VERSION ""

NS_ :

BS_:

BU_:
VAL_TABLE_ OdoDTCFrameSelr 1 "The last security event request" 0 "The first security event request" ;
VAL_TABLE_ OdometerRoutineRequestToHMI 7 "NA" 6 "Reserved" 5 "Reserved" 4 "ResetBackupODM_Storage " 3 "ClearNotActiveODM_DTC " 2 "ReadOdometerDTC" 1 "WriteDCUOdometerValueToHMI" 0 "RetrieveOdometerBackupValue" ;
VAL_TABLE_ ODM_StatusFlags 3 "Reserved" 2 "NA" 1 "Fault" 0 "NoFault" ;

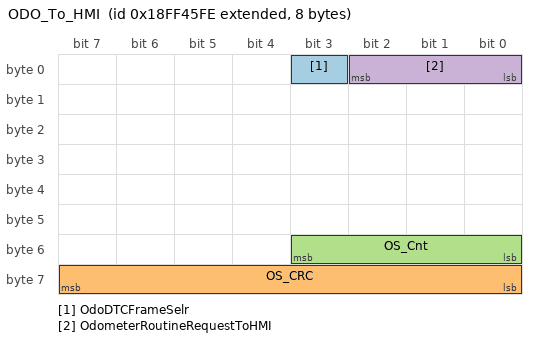
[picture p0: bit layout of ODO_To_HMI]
BO_ 2566866430 ODO_To_HMI: 8 Vector__XXX
 SG_ OdoDTCFrameSelr : 3|1@1+ (1,0) [0|0] "" Vector__XXX
 SG_ OS_CRC : 56|8@1+ (1,0) [0|255] "" Vector__XXX
 SG_ OS_Cnt : 48|4@1+ (1,0) [0|15] "" Vector__XXX
 SG_ OdometerRoutineRequestToHMI : 0|3@1+ (1,0) [0|7] "" Vector__XXX

CM_ SG_ 2566866430 OdoDTCFrameSelr "Odometer DTC Frame selector for request to HMI";
CM_ SG_ 2566866430 OdometerRoutineRequestToHMI "Request routines execution to HMI as a part of Odometer service routine.";
BA_DEF_ SG_  "SigType" ENUM  "Default","Range","RangeSigned","ASCII","Discrete","Control","ReferencePGN","DTC","StringDelimiter","StringLength","StringLengthControl","MessageCounter","MessageChecksum";
BA_DEF_ SG_  "GenSigEVName" STRING ;
BA_DEF_ SG_  "GenSigILSupport" ENUM  "No","Yes";
BA_DEF_ SG_  "GenSigSendType" ENUM  "Cyclic","OnWrite","OnWriteWithRepetition","OnChange","OnChangeWithRepetition","IfActive","IfActiveWithRepetition","NoSigSendType";
BA_DEF_ SG_  "GenSigStartValue" INT 0 2147483647;
BA_DEF_ BO_  "GenMsgILSupport" ENUM  "No","Yes";
BA_DEF_ BU_  "NmStationAddress" INT 0 255;
BA_DEF_ BO_  "GenMsgSendType" ENUM  "cyclic","NotUsed","IfActive","NotUsed","NotUsed","NotUsed","NotUsed","NotUsed","noMsgSendType";
BA_DEF_ BO_  "GenMsgRequestable" INT 0 1;
BA_DEF_ BO_  "GenMsgCycleTime" INT 0 3600000;
BA_DEF_  "DBName" STRING ;
BA_DEF_  "BusType" STRING ;
BA_DEF_  "ProtocolType" STRING ;
BA_DEF_ BO_  "VFrameFormat" ENUM  "StandardCAN","ExtendedCAN","reserved","J1939PG";
BA_DEF_ BO_  "Producer" STRING ;
BA_DEF_DEF_ "Producer" "DTS" ;
BA_DEF_DEF_  "SigType" "Default";
BA_DEF_DEF_  "GenSigEVName" "Env@Nodename_@Signame";
BA_DEF_DEF_  "GenSigILSupport" "Yes";
BA_DEF_DEF_  "GenSigSendType" "NoSigSendType";
BA_DEF_DEF_  "GenSigStartValue" 0;
BA_DEF_DEF_  "GenMsgILSupport" "Yes";
BA_DEF_DEF_  "NmStationAddress" 254;
BA_DEF_DEF_  "GenMsgSendType" "noMsgSendType";
BA_DEF_DEF_  "GenMsgRequestable" 1;
BA_DEF_DEF_  "GenMsgCycleTime" 0;
BA_DEF_DEF_  "DBName" "";
BA_DEF_DEF_  "BusType" "CAN";
BA_DEF_DEF_  "ProtocolType" "J1939";
BA_DEF_DEF_  "VFrameFormat" "J1939PG";
BA_ "DBName" "J1939Template";
BA_ "GenMsgSendType" BO_ 2566866430 0;
BA_ "GenMsgCycleTime" BO_ 2566866430 100;
BA_ "SigType" SG_ 2566866430 OS_CRC 12;
BA_ "SigType" SG_ 2566866430 OS_Cnt 11;
BA_ "GenSigStartValue" SG_ 2566866430 OdometerRoutineRequestToHMI 7;
VAL_ 2566866430 OdoDTCFrameSelr 1 "The last security event request" 0 "The first security event request" ;
VAL_ 2566866430 OdometerRoutineRequestToHMI 7 "NA" 6 "Reserved" 5 "ResetBackupODM_Storage " 4 "ClearNotActiveODM_DTC " 3 "ReadOdometerDTC" 2 "WriteDCUOdometerValueToHMI" 1 "RetrieveOdometerBackupValue" 0 "NoRequest" ;
